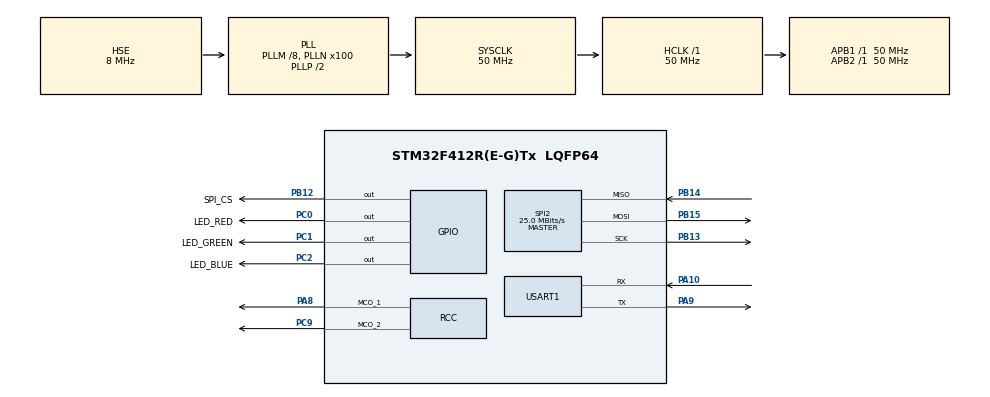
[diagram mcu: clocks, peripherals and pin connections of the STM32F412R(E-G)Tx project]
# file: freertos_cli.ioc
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Dma.Request0=USART1_RX
Dma.Request1=USART1_TX
Dma.USART1_RX.0.Direction=DMA_PERIPH_TO_MEMORY
Dma.USART1_RX.0.FIFOMode=DMA_FIFOMODE_DISABLE
Dma.USART1_RX.0.Instance=DMA2_Stream2
Dma.USART1_RX.0.MemDataAlignment=DMA_MDATAALIGN_BYTE
Dma.USART1_RX.0.MemInc=DMA_MINC_ENABLE
Dma.USART1_RX.0.Mode=DMA_NORMAL
Dma.USART1_RX.0.PeriphDataAlignment=DMA_PDATAALIGN_BYTE
Dma.USART1_RX.0.PeriphInc=DMA_PINC_DISABLE
Dma.USART1_RX.0.Priority=DMA_PRIORITY_LOW
Dma.USART1_TX.1.Direction=DMA_MEMORY_TO_PERIPH
Dma.USART1_TX.1.FIFOMode=DMA_FIFOMODE_DISABLE
Dma.USART1_TX.1.Instance=DMA2_Stream7
Dma.USART1_TX.1.MemDataAlignment=DMA_MDATAALIGN_BYTE
Dma.USART1_TX.1.MemInc=DMA_MINC_ENABLE
Dma.USART1_TX.1.Mode=DMA_NORMAL
Dma.USART1_TX.1.PeriphDataAlignment=DMA_PDATAALIGN_BYTE
Dma.USART1_TX.1.PeriphInc=DMA_PINC_DISABLE
Dma.USART1_TX.1.Priority=DMA_PRIORITY_LOW
FREERTOS.Tasks01=defaultTask,0,128,StartDefaultTask,Default,NULL,Dynamic,NULL,NULL
FREERTOS.configENABLE_FPU=1
FREERTOS.configGENERATE_RUN_TIME_STATS=1
FREERTOS.configUSE_NEWLIB_REENTRANT=1
FREERTOS.configUSE_STATS_FORMATTING_FUNCTIONS=1
FREERTOS.configUSE_TRACE_FACILITY=1
Mcu.Family=STM32F4
Mcu.Name=STM32F412R(E-G)Tx
Mcu.Package=LQFP64
NVIC.DMA2_Stream2_IRQn=true\:5\:0\:false\:false\:true\:true\:false\:true\:true
NVIC.DMA2_Stream7_IRQn=true\:5\:0\:false\:false\:true\:true\:false\:true\:true
NVIC.PriorityGroup=NVIC_PRIORITYGROUP_4
NVIC.TIM1_UP_TIM10_IRQn=true\:15\:0\:false\:false\:true\:false\:false\:true\:true
NVIC.TimeBase=TIM1_UP_TIM10_IRQn
NVIC.TimeBaseIP=TIM1
NVIC.USART1_IRQn=true\:5\:0\:false\:false\:true\:true\:true\:true\:true
PA10.Mode=Asynchronous
PA10.Signal=USART1_RX
PA13.Mode=Serial_Wire
PA13.Signal=SYS_JTMS-SWDIO
PA14.Mode=Serial_Wire
PA14.Signal=SYS_JTCK-SWCLK
PA8.Mode=Clock-out-1
PA8.Signal=RCC_MCO_1
PA9.Mode=Asynchronous
PA9.Signal=USART1_TX
PB12.GPIO_Label=SPI_CS
PB12.GPIO_ModeDefaultOutputPP=GPIO_MODE_OUTPUT_PP
PB12.GPIO_PuPd=GPIO_PULLUP
PB12.GPIO_Speed=GPIO_SPEED_FREQ_HIGH
PB12.PinState=GPIO_PIN_SET
PB12.Signal=GPIO_Output
PB13.Mode=Full_Duplex_Master
PB13.Signal=SPI2_SCK
PB14.Mode=Full_Duplex_Master
PB14.Signal=SPI2_MISO
PB15.Mode=Full_Duplex_Master
PB15.Signal=SPI2_MOSI
PC0.GPIO_Label=LED_RED
PC0.GPIO_ModeDefaultOutputPP=GPIO_MODE_OUTPUT_PP
PC0.GPIO_PuPd=GPIO_PULLUP
PC0.GPIO_Speed=GPIO_SPEED_FREQ_HIGH
PC0.PinState=GPIO_PIN_SET
PC0.Signal=GPIO_Output
PC1.GPIO_Label=LED_GREEN
PC1.GPIO_ModeDefaultOutputPP=GPIO_MODE_OUTPUT_PP
PC1.GPIO_PuPd=GPIO_PULLUP
PC1.GPIO_Speed=GPIO_SPEED_FREQ_HIGH
PC1.PinState=GPIO_PIN_SET
PC1.Signal=GPIO_Output
PC14-OSC32_IN.Mode=LSE-External-Oscillator
PC14-OSC32_IN.Signal=RCC_OSC32_IN
PC15-OSC32_OUT.Mode=LSE-External-Oscillator
PC15-OSC32_OUT.Signal=RCC_OSC32_OUT
PC2.GPIO_Label=LED_BLUE
PC2.GPIO_ModeDefaultOutputPP=GPIO_MODE_OUTPUT_PP
PC2.GPIO_PuPd=GPIO_PULLUP
PC2.GPIO_Speed=GPIO_SPEED_FREQ_HIGH
PC2.PinState=GPIO_PIN_SET
PC2.Signal=GPIO_Output
PC9.Mode=Clock-out-2
PC9.Signal=RCC_MCO_2
PH0\ -\ OSC_IN.Mode=HSE-External-Oscillator
PH0\ -\ OSC_IN.Signal=RCC_OSC_IN
PH1\ -\ OSC_OUT.Mode=HSE-External-Oscillator
PH1\ -\ OSC_OUT.Signal=RCC_OSC_OUT
ProjectManager.HeapSize=0x200
ProjectManager.StackSize=0x400
ProjectManager.TargetToolchain=STM32CubeIDE
RCC.AHBFreq_Value=50000000
RCC.APB1Freq_Value=50000000
RCC.APB1TimFreq_Value=50000000
RCC.APB2Freq_Value=50000000
RCC.APB2TimFreq_Value=50000000
RCC.CortexFreq_Value=50000000
RCC.HCLKFreq_Value=50000000
RCC.HSE_VALUE=8000000
RCC.PLLM=8
RCC.PLLN=100
RCC.PLLSourceVirtual=RCC_PLLSOURCE_HSE
RCC.SYSCLKFreq_VALUE=50000000
RCC.SYSCLKSource=RCC_SYSCLKSOURCE_PLLCLK
RCC.USBFreq_Value=50000000
RCC.VCOOutputFreq_Value=100000000
SPI2.CalculateBaudRate=25.0 MBits/s
SPI2.Direction=SPI_DIRECTION_2LINES
SPI2.Mode=SPI_MODE_MASTER
SPI2.VirtualType=VM_MASTER
USART1.VirtualMode=VM_ASYNC
VP_FREERTOS_VS_CMSIS_V1.Mode=CMSIS_V1
VP_SYS_VS_tim1.Mode=TIM1
board=custom

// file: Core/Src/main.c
/* USER CODE BEGIN Header */
/**
  ******************************************************************************
  * @file           : main.c
  * @brief          : Main program body
  ******************************************************************************
  * @attention
  *
  * Copyright (c) 2024 STMicroelectronics.
  * All rights reserved.
  *
  * This software is licensed under terms that can be found in the LICENSE file
  * in the root directory of this software component.
  * If no LICENSE file comes with this software, it is provided AS-IS.
  *
  ******************************************************************************
  */
/* USER CODE END Header */
#include "main.h"
#include "cmsis_os.h"

/* USER CODE BEGIN Includes */
#include "cli_uart_interface.h"
/* USER CODE END Includes */

SPI_HandleTypeDef hspi2;

UART_HandleTypeDef huart1;
DMA_HandleTypeDef hdma_usart1_rx;
DMA_HandleTypeDef hdma_usart1_tx;

osThreadId defaultTaskHandle;

void SystemClock_Config(void);
static void MX_GPIO_Init(void);
static void MX_DMA_Init(void);
static void MX_SPI2_Init(void);
static void MX_USART1_UART_Init(void);
void StartDefaultTask(void const * argument);

int main(void)
{

  /* MCU Configuration--------------------------------------------------------*/

  /* Reset of all peripherals, Initializes the Flash interface and the Systick. */
  HAL_Init();

  /* Configure the system clock */
  SystemClock_Config();

  /* Initialize all configured peripherals */
  MX_GPIO_Init();
  MX_DMA_Init();
  MX_SPI2_Init();
  MX_USART1_UART_Init();
  /* USER CODE BEGIN 2 */
  CLI_UART_Thread_Add();
  /* USER CODE END 2 */

  /* Create the thread(s) */
  /* definition and creation of defaultTask */
  osThreadDef(defaultTask, StartDefaultTask, osPriorityNormal, 0, 128);
  defaultTaskHandle = osThreadCreate(osThread(defaultTask), NULL);

  /* Start scheduler */
  osKernelStart();

  /* We should never get here as control is now taken by the scheduler */

  /* Infinite loop */
  while (1)
  {

  }
}

void SystemClock_Config(void)
{
  RCC_OscInitTypeDef RCC_OscInitStruct = {0};
  RCC_ClkInitTypeDef RCC_ClkInitStruct = {0};

  /** Configure the main internal regulator output voltage
  */
  __HAL_RCC_PWR_CLK_ENABLE();
  __HAL_PWR_VOLTAGESCALING_CONFIG(PWR_REGULATOR_VOLTAGE_SCALE1);

  /** Initializes the RCC Oscillators according to the specified parameters
  * in the RCC_OscInitTypeDef structure.
  */
  RCC_OscInitStruct.OscillatorType = RCC_OSCILLATORTYPE_HSI|RCC_OSCILLATORTYPE_HSE;
  RCC_OscInitStruct.HSEState = RCC_HSE_ON;
  RCC_OscInitStruct.HSIState = RCC_HSI_ON;
  RCC_OscInitStruct.HSICalibrationValue = RCC_HSICALIBRATION_DEFAULT;
  RCC_OscInitStruct.PLL.PLLState = RCC_PLL_ON;
  RCC_OscInitStruct.PLL.PLLSource = RCC_PLLSOURCE_HSE;
  RCC_OscInitStruct.PLL.PLLM = 8;
  RCC_OscInitStruct.PLL.PLLN = 100;
  RCC_OscInitStruct.PLL.PLLP = RCC_PLLP_DIV2;
  RCC_OscInitStruct.PLL.PLLQ = 2;
  RCC_OscInitStruct.PLL.PLLR = 2;
  if (HAL_RCC_OscConfig(&RCC_OscInitStruct) != HAL_OK)
  {
    Error_Handler();
  }

  /** Initializes the CPU, AHB and APB buses clocks
  */
  RCC_ClkInitStruct.ClockType = RCC_CLOCKTYPE_HCLK|RCC_CLOCKTYPE_SYSCLK
                              |RCC_CLOCKTYPE_PCLK1|RCC_CLOCKTYPE_PCLK2;
  RCC_ClkInitStruct.SYSCLKSource = RCC_SYSCLKSOURCE_PLLCLK;
  RCC_ClkInitStruct.AHBCLKDivider = RCC_SYSCLK_DIV1;
  RCC_ClkInitStruct.APB1CLKDivider = RCC_HCLK_DIV1;
  RCC_ClkInitStruct.APB2CLKDivider = RCC_HCLK_DIV1;

  if (HAL_RCC_ClockConfig(&RCC_ClkInitStruct, FLASH_LATENCY_1) != HAL_OK)
  {
    Error_Handler();
  }
  HAL_RCC_MCOConfig(RCC_MCO1, RCC_MCO1SOURCE_HSI, RCC_MCODIV_1);
  HAL_RCC_MCOConfig(RCC_MCO2, RCC_MCO2SOURCE_SYSCLK, RCC_MCODIV_1);
}

static void MX_SPI2_Init(void)
{

  /* SPI2 parameter configuration*/
  hspi2.Instance = SPI2;
  hspi2.Init.Mode = SPI_MODE_MASTER;
  hspi2.Init.Direction = SPI_DIRECTION_2LINES;
  hspi2.Init.DataSize = SPI_DATASIZE_8BIT;
  hspi2.Init.CLKPolarity = SPI_POLARITY_LOW;
  hspi2.Init.CLKPhase = SPI_PHASE_1EDGE;
  hspi2.Init.NSS = SPI_NSS_SOFT;
  hspi2.Init.BaudRatePrescaler = SPI_BAUDRATEPRESCALER_2;
  hspi2.Init.FirstBit = SPI_FIRSTBIT_MSB;
  hspi2.Init.TIMode = SPI_TIMODE_DISABLE;
  hspi2.Init.CRCCalculation = SPI_CRCCALCULATION_DISABLE;
  hspi2.Init.CRCPolynomial = 10;
  if (HAL_SPI_Init(&hspi2) != HAL_OK)
  {
    Error_Handler();
  }

}

static void MX_USART1_UART_Init(void)
{

  huart1.Instance = USART1;
  huart1.Init.BaudRate = 115200;
  huart1.Init.WordLength = UART_WORDLENGTH_8B;
  huart1.Init.StopBits = UART_STOPBITS_1;
  huart1.Init.Parity = UART_PARITY_NONE;
  huart1.Init.Mode = UART_MODE_TX_RX;
  huart1.Init.HwFlowCtl = UART_HWCONTROL_NONE;
  huart1.Init.OverSampling = UART_OVERSAMPLING_16;
  if (HAL_UART_Init(&huart1) != HAL_OK)
  {
    Error_Handler();
  }

}

static void MX_DMA_Init(void)
{

  /* DMA controller clock enable */
  __HAL_RCC_DMA2_CLK_ENABLE();

  /* DMA interrupt init */
  /* DMA2_Stream2_IRQn interrupt configuration */
  HAL_NVIC_SetPriority(DMA2_Stream2_IRQn, 5, 0);
  HAL_NVIC_EnableIRQ(DMA2_Stream2_IRQn);
  /* DMA2_Stream7_IRQn interrupt configuration */
  HAL_NVIC_SetPriority(DMA2_Stream7_IRQn, 5, 0);
  HAL_NVIC_EnableIRQ(DMA2_Stream7_IRQn);

}

static void MX_GPIO_Init(void)
{
  GPIO_InitTypeDef GPIO_InitStruct = {0};

  /* GPIO Ports Clock Enable */
  __HAL_RCC_GPIOC_CLK_ENABLE();
  __HAL_RCC_GPIOH_CLK_ENABLE();
  __HAL_RCC_GPIOB_CLK_ENABLE();
  __HAL_RCC_GPIOA_CLK_ENABLE();

  /*Configure GPIO pin Output Level */
  HAL_GPIO_WritePin(GPIOC, LED_RED_Pin|LED_GREEN_Pin|LED_BLUE_Pin, GPIO_PIN_SET);

  /*Configure GPIO pin Output Level */
  HAL_GPIO_WritePin(SPI_CS_GPIO_Port, SPI_CS_Pin, GPIO_PIN_SET);

  /*Configure GPIO pins : LED_RED_Pin LED_GREEN_Pin LED_BLUE_Pin */
  GPIO_InitStruct.Pin = LED_RED_Pin|LED_GREEN_Pin|LED_BLUE_Pin;
  GPIO_InitStruct.Mode = GPIO_MODE_OUTPUT_PP;
  GPIO_InitStruct.Pull = GPIO_PULLUP;
  GPIO_InitStruct.Speed = GPIO_SPEED_FREQ_HIGH;
  HAL_GPIO_Init(GPIOC, &GPIO_InitStruct);

  /*Configure GPIO pin : SPI_CS_Pin */
  GPIO_InitStruct.Pin = SPI_CS_Pin;
  GPIO_InitStruct.Mode = GPIO_MODE_OUTPUT_PP;
  GPIO_InitStruct.Pull = GPIO_PULLUP;
  GPIO_InitStruct.Speed = GPIO_SPEED_FREQ_HIGH;
  HAL_GPIO_Init(SPI_CS_GPIO_Port, &GPIO_InitStruct);

  /*Configure GPIO pin : PC9 */
  GPIO_InitStruct.Pin = GPIO_PIN_9;
  GPIO_InitStruct.Mode = GPIO_MODE_AF_PP;
  GPIO_InitStruct.Pull = GPIO_NOPULL;
  GPIO_InitStruct.Speed = GPIO_SPEED_FREQ_LOW;
  GPIO_InitStruct.Alternate = GPIO_AF0_MCO;
  HAL_GPIO_Init(GPIOC, &GPIO_InitStruct);

  /*Configure GPIO pin : PA8 */
  GPIO_InitStruct.Pin = GPIO_PIN_8;
  GPIO_InitStruct.Mode = GPIO_MODE_AF_PP;
  GPIO_InitStruct.Pull = GPIO_NOPULL;
  GPIO_InitStruct.Speed = GPIO_SPEED_FREQ_LOW;
  GPIO_InitStruct.Alternate = GPIO_AF0_MCO;
  HAL_GPIO_Init(GPIOA, &GPIO_InitStruct);

/* USER CODE BEGIN MX_GPIO_Init_2 */
  HAL_GPIO_WritePin(SPI_CS_GPIO_Port, SPI_CS_Pin, 1);
/* USER CODE END MX_GPIO_Init_2 */
}

void StartDefaultTask(void const * argument)
{
  /* USER CODE BEGIN 5 */
  /* Infinite loop */
  for(;;)
  {
    //osDelay(1);
	HAL_GPIO_TogglePin(LED_GREEN_GPIO_Port, LED_GREEN_Pin);
	osDelay(200);
  }
  /* USER CODE END 5 */
}

void HAL_TIM_PeriodElapsedCallback(TIM_HandleTypeDef *htim)
{
  if (htim->Instance == TIM1) {
    HAL_IncTick();
  }
}

void Error_Handler(void)
{
  __disable_irq();
  while (1)
  {
  }
}
